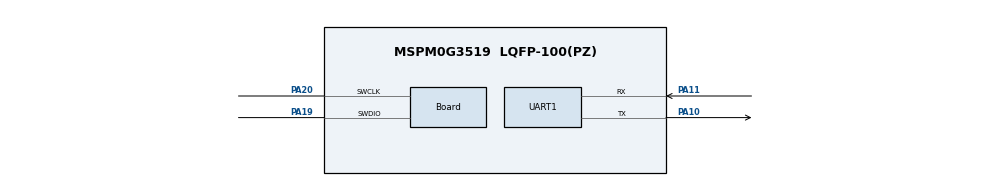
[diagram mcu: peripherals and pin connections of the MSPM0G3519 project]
//@cliArgs --device "MSPM0G351X" --package "LQFP-100(PZ)" --part "Default"
//@v2CliArgs --device "MSPM0G3519" --package "LQFP-100(PZ)"
// @cliArgs --board /ti/boards/LP_MSPM0G3519 --rtos nortos
// UART0 on PA10 (TX) / PA11 (RX), the XDS110 back-channel with J12/J13 on XDS.
// DMA ch0 = UART RX (byte -> memory), DMA ch1 = UART TX (memory -> byte).
// Baud rate is NOT set here: usart_dma.c overrides it from the build-time define USART_BAUD.
const SYSCTL = scripting.addModule("/ti/driverlib/SYSCTL");
const UART   = scripting.addModule("/ti/driverlib/UART", {}, false);
const UART1  = UART.addInstance();
const TIMER  = scripting.addModule("/ti/driverlib/TIMER", {}, false);
const TIMER1 = TIMER.addInstance();


const Board                       = scripting.addModule("/ti/driverlib/Board", {}, false);
Board.peripheral.$assign          = "DEBUGSS";
Board.peripheral.swclkPin.$assign = "PA20";
Board.peripheral.swdioPin.$assign = "PA19";

SYSCTL.forceDefaultClkConfig = true;
SYSCTL.clockTreeEn           = true;

UART1.$name                             = "UART_0";
UART1.enableFIFO                        = true;
UART1.rxFifoThreshold                   = "DL_UART_RX_FIFO_LEVEL_ONE_ENTRY";
UART1.txFifoThreshold                   = "DL_UART_TX_FIFO_LEVEL_ONE_ENTRY";
UART1.enabledInterrupts                 = ["DMA_DONE_RX","DMA_DONE_TX"];
UART1.enabledDMARXTriggers              = "DL_UART_DMA_INTERRUPT_RX";
UART1.enabledDMATXTriggers              = "DL_UART_DMA_INTERRUPT_TX";
UART1.peripheral.$assign                = "UART0";
UART1.peripheral.rxPin.$assign          = "PA11";
UART1.peripheral.txPin.$assign          = "PA10";
UART1.DMA_CHANNEL_RX.$name              = "DMA_RX";
UART1.DMA_CHANNEL_RX.addressMode        = "f2b";
UART1.DMA_CHANNEL_RX.dstLength          = "BYTE";
UART1.DMA_CHANNEL_RX.srcLength          = "BYTE";
UART1.DMA_CHANNEL_RX.peripheral.$assign = "DMA_CH0";
UART1.DMA_CHANNEL_TX.$name              = "DMA_TX";
UART1.DMA_CHANNEL_TX.addressMode        = "b2f";
UART1.DMA_CHANNEL_TX.dstLength          = "BYTE";
UART1.DMA_CHANNEL_TX.srcLength          = "BYTE";
UART1.DMA_CHANNEL_TX.peripheral.$assign = "DMA_CH1";

// 1 ms tick: stands in for the IDLE-line interrupt (see usart_dma.c)
TIMER1.$name              = "TIMER_IDLE";
TIMER1.timerClkSrc        = "BUSCLK";
TIMER1.timerClkDiv        = 1;
TIMER1.timerClkPrescale   = 32;
TIMER1.timerMode          = "PERIODIC";
TIMER1.timerPeriod        = "1 ms";
TIMER1.interrupts         = ["ZERO"];
TIMER1.peripheral.$assign = "TIMG0";

const ProjectConfig              = scripting.addModule("/ti/project_config/ProjectConfig", {}, false);
ProjectConfig.migrationCondition = true;
